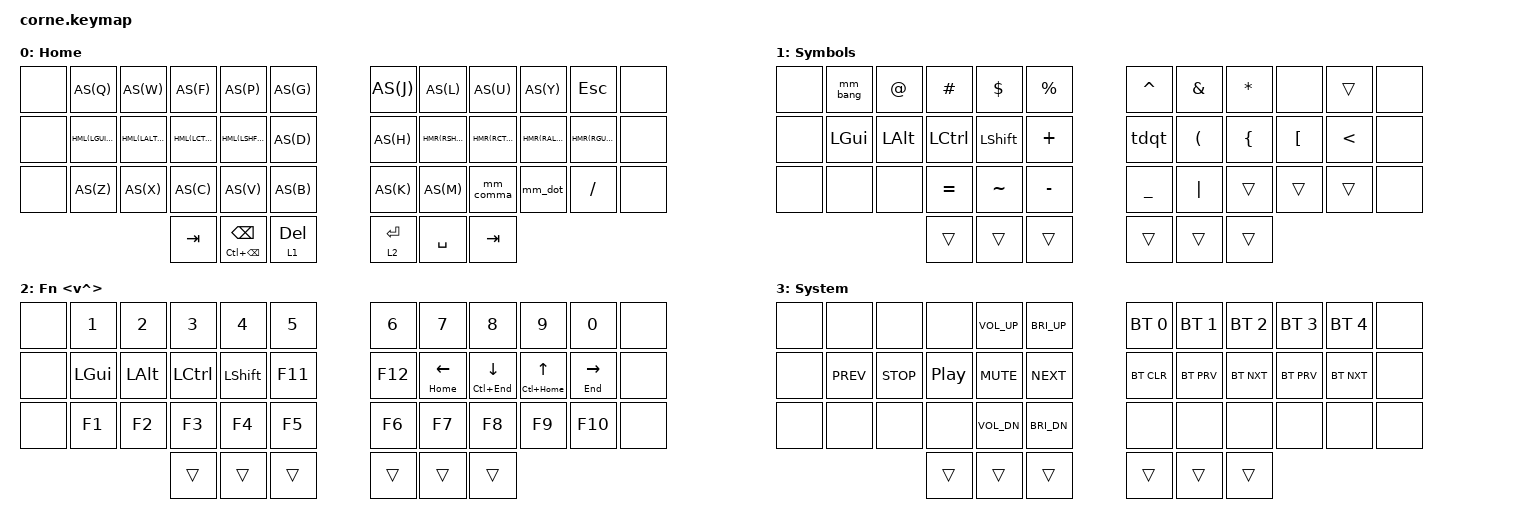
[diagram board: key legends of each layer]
#include <behaviors.dtsi>
#include <dt-bindings/zmk/keys.h>
#include <dt-bindings/zmk/bt.h>
// #include <dt-bindings/zmk/mouse.h>

/*        42 KEY MATRIX / LAYOUT MAPPING
  ╭──┬────────────────╮╭────────────────┬──╮
  │ 0│  1  2  3  4  5 ││  6  7  8  9 10 │11│
  │12│ 13 14 15 16 17 ││ 18 19 20 21 22 │23│
  │24│ 25 26 27 28 29 ││ 30 31 32 33 34 │35│
  ╰──┴─────╮ 36 37 38 ││ 39 40 41╭──────┴──╯
           ╰──────────╯╰─────────╯
*/
#define KEYS_L 0 1 2 3 4 5   12 13 14 15 16 17   24 25 26 27 28 29
#define KEYS_R 6 7 8 9 10 11   18 19 20 21 22 23   30 31 32 33 34 35
#define KEYS_T 36 37 38 39 40 41

// #include "macros.dtsi"
#define XXX &none
#define ___ &trans

#define HOME_L 0
#define SYM_L 1
#define NUM_L 2
#define HARDWARE_L 3

#define NAV_LEFT  &mt HOME   LEFT   // tap: left  | long-tap: start of line
#define NAV_RIGHT &mt END    RIGHT  // tap: right | long-tap: end   of line
#define NAV_UP    &mt LC(HOME) UP   // tap: up    | long-tap: start of document
#define NAV_DOWN  &mt LC(END)  DOWN // tap: down  | long-tap: end   of document
#define NAV_BSPC  &mt LC(BSPC) BSPC // tap: bspc  | long-tap: delete prev word

#define MO_TOG(layer) &mo_tog layer layer

// #define AS(keycode) &as LS(keycode) keycode     // Autoshift Macro
#define AS(keycode) &as keycode keycode     // Autoshift Macro
#define HML(k1, k2) &hml k1 k2
#define HMR(k1, k2) &hmr k1 k2

/ {
   conditional_layers {
      compatible = "zmk,conditional-layers";
      tri_layer {
         if-layers = <1 2>;
         then-layer = <3>;
      };
   };
   // macros {
   //      delete_word: delete_word {
   //          label = "Delete_Word";
   //          compatible = "zmk,behavior-macro";
   //          #binding-cells = <0>;
   //          bindings
   //              = <&macro_press &kp LCTRL>
   //              , <&macro_tap &kp BACKSPACE>
   //              , <&macro_release &kp LCTRL>
   //              ;
   //      };
   // };
   behaviors {
      // td0: tap_dance_0 {
      //    compatible = "zmk,behavior-hold-tap";
      //    label = "TAP_DANCE_0";
      //    #binding-cells = <2>;
      //    flavor = "hold-preferred";
      //    tapping-term-ms = <200>;
      //    bindings = <&mo>, <&kp>;
      // };
      // td1: tap_dance_1 {
      //    compatible = "zmk,behavior-hold-tap";
      //    label = "TAP_DANCE_1";
      //    #binding-cells = <0>;
      //    flavor = "hold-preferred";
      //    tapping-term-ms = <200>;
      //    bindings = <&mo 2>, <&kp RETURN>;
      // };
      // tdbs: tap_dance_bs {
      //    compatible = "zmk,behavior-tap-dance";
      //    label = "TAP_DANCE_BS";
      //    #binding-cells = <0>;
      //    tapping-term-ms = <200>;
      //    bindings = <&kp BACKSPACE>, <&delete_word>;
      // };
      tdqt: tap_dance_qt {
         compatible = "zmk,behavior-tap-dance";
         label = "TAP_DANCE_QT";
         #binding-cells = <0>;
         tapping-term-ms = <200>;
         bindings = <&kp SQT>, <&kp DQT>, <&kp GRAVE>;
      };
      as: auto_shift {
         compatible = "zmk,behavior-hold-tap";
         label = "AUTO_SHIFT";
         #binding-cells = <2>;
         tapping_term_ms = <135>;
         quick_tap_ms = <0>;
         flavor = "tap-preferred";
         bindings = <&kp>, <&kp>;
      };
      mm_comma: comma_morph {
         compatible = "zmk,behavior-mod-morph";
         label = "COMMA_MORPH";
         #binding-cells = <0>;
         bindings = <&kp COMMA>, <&kp SEMICOLON>;
         mods = <(MOD_LSFT|MOD_RSFT)>;
      };
      mm_dot: dot_morph {
         compatible = "zmk,behavior-mod-morph";
         label = "DOT_MORPH";
         #binding-cells = <0>;
         bindings = <&kp DOT>, <&kp COLON>;
         mods = <(MOD_LSFT|MOD_RSFT)>;
      };
      mm_bang: bang_morph {
         compatible = "zmk,behavior-mod-morph";
         label = "BANG_MORPH";
         #binding-cells = <0>;
         bindings = <&kp QMARK>, <&kp EXCL>;
         mods = <(MOD_LSFT|MOD_RSFT)>;
      };
      mm_bs: bs_morph {
         compatible = "zmk,behavior-mod-morph";
         label = "BS_MORPH";
         #binding-cells = <0>;
         bindings = <&kp BACKSPACE>, <&kp DELETE>;
         mods = <(MOD_LSFT|MOD_RSFT)>;
         keep-mods = <MOD_RSFT>;
      };
      // bspc_del: backspace_delete {
      //    compatible = "zmk,behavior-mod-morph";
      //    label = "BACKSPACE_DELETE";
      //    #binding-cells = <0>;
      //    bindings = <&kp BACKSPACE>, <&kp DELETE>;
      //    mods = <(MOD_LSFT|MOD_RSFT)>; // Shift
      // };
      hml: left_homerow_mods {
         compatible = "zmk,behavior-hold-tap";
         label = "LEFT_HOMEROW_MODS";
         #binding-cells = <2>;
         tapping-term-ms = <150>;
         quick-tap-ms = <0>;
         flavor = "tap-unless-interrupted";
         bindings = <&kp>, <&kp>;
         hold-trigger-key-positions = <KEYS_R>;
      };
      hmr: right_homerow_mods {
         compatible = "zmk,behavior-hold-tap";
         label = "RIGHT_HOMEROW_MODS";
         #binding-cells = <2>;
         tapping-term-ms = <150>;
         quick-tap-ms = <0>;
         flavor = "tap-unless-interrupted";
         bindings = <&kp>, <&kp>;
         hold-trigger-key-positions = <KEYS_L>;
      };
      mo_tog: behavior_mo_tog {
         compatible = "zmk,behavior-hold-tap";
         label = "mo_tog";
         #binding-cells = <2>;
         flavor = "hold-preferred";
         tapping-term-ms = <200>;
         bindings = <&mo>, <&tog>;
      };
   };
   keymap {
      compatible = "zmk,keymap";
      home_layer {
         label = "Home";
         bindings = <
//╭───╮╭───────────┬───────────┬────────────┬────────────┬─────╮ ╭─────┬────────────┬────────────┬───────────┬───────────╮╭───╮
   XXX  AS(Q)       AS(W)       AS(F)        AS(P)        AS(G)   AS(J) AS(L)        AS(U)        AS(Y)       &kp ESCAPE   XXX
//├───┤├───────────┼───────────┼────────────┼────────────┼─────┤ ├─────┼────────────┼────────────┼───────────┼───────────┤├───┤
   XXX  HML(LGUI,A) HML(LALT,R) HML(LCTRL,S) HML(LSHFT,T) AS(D)   AS(H) HMR(RSHFT,N) HMR(RCTRL,E) HMR(RALT,I) HMR(RGUI,O)  XXX
//├───┤├───────────┼───────────┼────────────┼────────────┼─────┤ ├─────┼────────────┼────────────┼───────────┼───────────┤├───┤
   XXX  AS(Z)       AS(X)       AS(C)        AS(V)        AS(B)   AS(K) AS(M)        &mm_comma &mm_dot  &kp FSLH     XXX
//╰───╯╰───────────┴───────────┼────────────┼────────────┼─────┤ ├─────┼────────────┼────────────┴───────────┴───────────╯╰───╯
                                &kp TAB      NAV_BSPC     &lt 1 DELETE &lt 2 RETURN &kp SPACE    &kp TAB 
//                             ╰────────────┴────────────┴─────╯ ╰─────┴────────────┴────────────╯
>;
                };
      sym_layer {
         label = "Symbols";
         bindings = <
//╭───╮╭────────┬────────┬─────────┬─────────┬─────────╮ ╭─────────┬─────────────┬────────┬────────┬──────╮╭───╮
   XXX  &mm_bang &kp AT   &kp HASH  &kp DLLR  &kp PRCNT   &kp CARET &kp AMPERSAND &kp STAR XXX      ___     XXX
//├───┤├────────┼────────┼─────────┼─────────┼─────────┤ ├─────────┼─────────────┼────────┼────────┼──────┤├───┤
   XXX  &kp LGUI &kp LALT &kp LCTRL &kp LSHFT &kp PLUS    &tdqt     &kp LPAR      &kp LBRC &kp LBKT &kp LT  XXX
//├───┤├────────┼────────┼─────────┼─────────┼─────────┤ ├─────────┼─────────────┼────────┼────────┼──────┤├───┤
   XXX  XXX      XXX      &kp EQUAL &kp TILDE &kp MINUS   &kp UNDER &kp PIPE      ___      ___      ___     XXX
//╰───╯╰────────┴────────┼─────────┼─────────┼─────────┤ ├─────────┼─────────────┼────────┴────────┴──────╯╰───╯
                          ___       ___       ___         ___       ___           ___
//                       ╰─────────┴─────────┴─────────╯ ╰─────────┴─────────────┴────────╯
>;
      };

      num_layer {
         label = "Fn <v^>";
         bindings = <
//╭───╮╭────────┬────────┬─────────┬──────────┬───────╮ ╭───────┬────────┬────────┬──────┬─────────╮╭───╮
   XXX  &kp N1   &kp N2   &kp N3    &kp N4     &kp N5    &kp N6  &kp N7   &kp N8   &kp N9 &kp N0     XXX
//├───┤├────────┼────────┼─────────┼──────────┼───────┤ ├───────┼────────┼────────┼──────┼─────────┤├───┤
   XXX  &kp LGUI &kp LALT &kp LCTRL &kp LSHIFT &kp F11   &kp F12 NAV_LEFT NAV_DOWN NAV_UP NAV_RIGHT  XXX
//├───┤├────────┼────────┼─────────┼──────────┼───────┤ ├───────┼────────┼────────┼──────┼─────────┤├───┤
   XXX  &kp F1   &kp F2   &kp F3    &kp F4     &kp F5    &kp F6  &kp F7   &kp F8   &kp F9 &kp F10    XXX
//╰───╯╰────────┴────────┼─────────┼──────────┼───────┤ ├───────┼────────┼────────┴──────┴─────────╯╰───╯
                    	     ___       ___        ___       ___     ___      ___
//                       ╰─────────┴──────────┴───────╯ ╰───────┴────────┴────────╯
>;
      };
      hw_layer {
         label = "System";
         bindings = <
//╭───╮╭──────────┬──────────┬────────┬────────────┬────────────╮ ╭────────────┬────────────┬────────────┬────────────┬────────────╮╭───╮
   XXX  XXX        XXX        XXX      &kp K_VOL_UP &kp C_BRI_UP   &bt BT_SEL 0 &bt BT_SEL 1 &bt BT_SEL 2 &bt BT_SEL 3 &bt BT_SEL 4  XXX
//├───┤├──────────┼──────────┼────────┼────────────┼────────────┤ ├────────────┼────────────┼────────────┼────────────┼────────────┤├───┤
   XXX  &kp C_PREV &kp C_STOP &kp C_PP &kp K_MUTE   &kp C_NEXT     &bt BT_CLR   &bt BT_PRV   &bt BT_NXT   &bt BT_PRV   &bt BT_NXT    XXX
//├───┤├──────────┼──────────┼────────┼────────────┼────────────┤ ├────────────┼────────────┼────────────┼────────────┼────────────┤├───┤
   XXX  XXX        XXX        XXX      &kp K_VOL_DN &kp C_BRI_DN   XXX          XXX          XXX          XXX          XXX           XXX
//╰───╯╰──────────┴──────────┼────────┼────────────┼────────────┤ ├────────────┼────────────┼────────────┴────────────┴────────────╯╰───╯
                    	         ___      ___          ___            ___          ___          ___
//                           ╰────────┴────────────┴────────────╯ ╰────────────┴────────────┴────────────╯
>;
      };
   };
};
